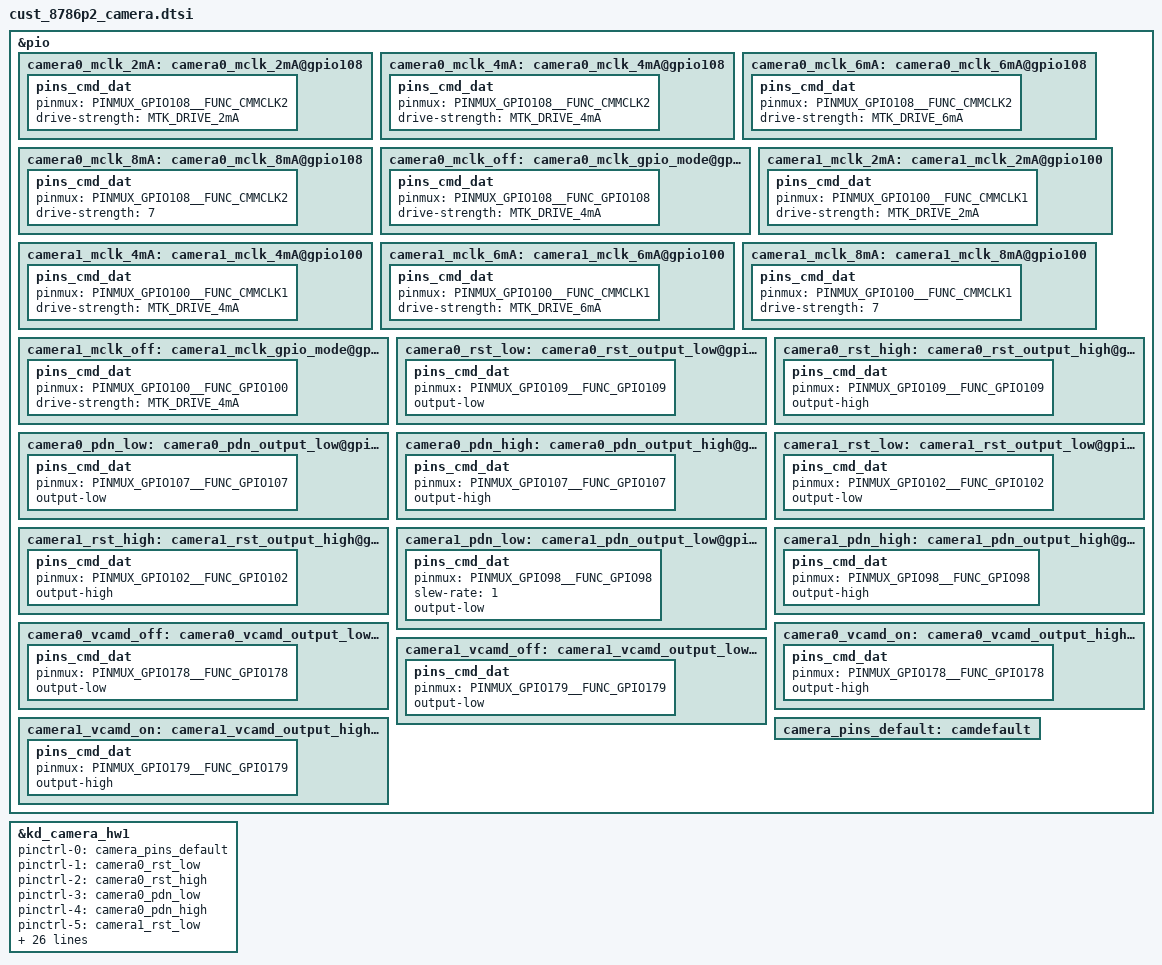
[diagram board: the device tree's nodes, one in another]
// SPDX-License-Identifier: GPL-2.0
/*
 * Copyright (c) 2018 MediaTek Inc.
 */
/* CAMERA GPIO standardization */
&pio {
	camera0_mclk_2mA: camera0_mclk_2mA@gpio108 {
		pins_cmd_dat {
			pinmux = <PINMUX_GPIO108__FUNC_CMMCLK2>;
			drive-strength = <MTK_DRIVE_2mA>;
		};
	};
	camera0_mclk_4mA: camera0_mclk_4mA@gpio108 {
		pins_cmd_dat {
			pinmux = <PINMUX_GPIO108__FUNC_CMMCLK2>;
			drive-strength = <MTK_DRIVE_4mA>;
		};
	};
	camera0_mclk_6mA: camera0_mclk_6mA@gpio108 {
		pins_cmd_dat {
			pinmux = <PINMUX_GPIO108__FUNC_CMMCLK2>;
			drive-strength = <MTK_DRIVE_6mA>;
		};
	};
	camera0_mclk_8mA: camera0_mclk_8mA@gpio108 {
		pins_cmd_dat {
			pinmux = <PINMUX_GPIO108__FUNC_CMMCLK2>;
			drive-strength = <7>;
		};
	};
	camera0_mclk_off: camera0_mclk_gpio_mode@gpio108 {
		pins_cmd_dat {
			pinmux = <PINMUX_GPIO108__FUNC_GPIO108>;
			drive-strength = <MTK_DRIVE_4mA>;
		};
	};
	camera1_mclk_2mA: camera1_mclk_2mA@gpio100 {
		pins_cmd_dat {
			pinmux = <PINMUX_GPIO100__FUNC_CMMCLK1>;
			drive-strength = <MTK_DRIVE_2mA>;
		};
	};
	camera1_mclk_4mA: camera1_mclk_4mA@gpio100 {
		pins_cmd_dat {
			pinmux = <PINMUX_GPIO100__FUNC_CMMCLK1>;
			drive-strength = <MTK_DRIVE_4mA>;
		};
	};
	camera1_mclk_6mA: camera1_mclk_6mA@gpio100 {
		pins_cmd_dat {
			pinmux = <PINMUX_GPIO100__FUNC_CMMCLK1>;
			drive-strength = <MTK_DRIVE_6mA>;
		};
	};
	camera1_mclk_8mA: camera1_mclk_8mA@gpio100 {
		pins_cmd_dat {
			pinmux = <PINMUX_GPIO100__FUNC_CMMCLK1>;
			drive-strength = <7>;
		};
	};
	camera1_mclk_off: camera1_mclk_gpio_mode@gpio100 {
		pins_cmd_dat {
			pinmux = <PINMUX_GPIO100__FUNC_GPIO100>;
			drive-strength = <MTK_DRIVE_4mA>;
		};
	};
	camera0_rst_low: camera0_rst_output_low@gpio109 {
		pins_cmd_dat {
			pinmux = <PINMUX_GPIO109__FUNC_GPIO109>;
			output-low;
		};
	};
	camera0_rst_high: camera0_rst_output_high@gpio109 {
		pins_cmd_dat {
			pinmux = <PINMUX_GPIO109__FUNC_GPIO109>;
			output-high;
		};
	};
	camera0_pdn_low: camera0_pdn_output_low@gpio107 {
		pins_cmd_dat {
			pinmux = <PINMUX_GPIO107__FUNC_GPIO107>;
			output-low;
		};
	};
	camera0_pdn_high: camera0_pdn_output_high@gpio107 {
		pins_cmd_dat {
			pinmux = <PINMUX_GPIO107__FUNC_GPIO107>;
			output-high;
		};
	};
	camera1_rst_low: camera1_rst_output_low@gpio102 {
		pins_cmd_dat {
			pinmux = <PINMUX_GPIO102__FUNC_GPIO102>;
			output-low;
		};
	};
	camera1_rst_high: camera1_rst_output_high@gpio102 {
		pins_cmd_dat {
			pinmux = <PINMUX_GPIO102__FUNC_GPIO102>;
			output-high;
		};
	};
	camera1_pdn_low: camera1_pdn_output_low@gpio98 {
		pins_cmd_dat {
			pinmux = <PINMUX_GPIO98__FUNC_GPIO98>;
			slew-rate = <1>;
			output-low;
		};
	};
	camera1_pdn_high: camera1_pdn_output_high@gpio98 {
		pins_cmd_dat {
			pinmux = <PINMUX_GPIO98__FUNC_GPIO98>;
			output-high;
		};
	};
	camera0_vcamd_off: camera0_vcamd_output_low@gpio178 {
		pins_cmd_dat {
			pinmux = <PINMUX_GPIO178__FUNC_GPIO178>;
			output-low;
		};
	};
	camera0_vcamd_on: camera0_vcamd_output_high@gpio178 {
		pins_cmd_dat {
			pinmux = <PINMUX_GPIO178__FUNC_GPIO178>;
			output-high;
		};
	};
	camera1_vcamd_off: camera1_vcamd_output_low@gpio179 {
		pins_cmd_dat {
			pinmux = <PINMUX_GPIO179__FUNC_GPIO179>;
			output-low;
		};
	};
	camera1_vcamd_on: camera1_vcamd_output_high@gpio179 {
		pins_cmd_dat {
			pinmux = <PINMUX_GPIO179__FUNC_GPIO179>;
			output-high;
		};
	};
	camera_pins_default: camdefault {
	};

};

&kd_camera_hw1 {
	pinctrl-names = "default",
			"cam0_rst0", "cam0_rst1",
			"cam0_pnd0", "cam0_pnd1",
			"cam1_rst0", "cam1_rst1",
			"cam1_pnd0", "cam1_pnd1",
			"cam0_vcamd_on",
			"cam0_vcamd_off",
			"cam1_vcamd_on",
			"cam1_vcamd_off",
			"cam0_mclk_off",
			"cam0_mclk_2mA", "cam0_mclk_4mA",
			"cam0_mclk_6mA", "cam0_mclk_8mA",
			"cam1_mclk_off",
			"cam1_mclk_2mA", "cam1_mclk_4mA",
			"cam1_mclk_6mA", "cam1_mclk_8mA";


	pinctrl-0 = <&camera_pins_default>;
	pinctrl-1 = <&camera0_rst_low>;
	pinctrl-2 = <&camera0_rst_high>;
	pinctrl-3 = <&camera0_pdn_low>;
	pinctrl-4 = <&camera0_pdn_high>;
	pinctrl-5 = <&camera1_rst_low>;
	pinctrl-6 = <&camera1_rst_high>;
	pinctrl-7 = <&camera1_pdn_low>;
	pinctrl-8 = <&camera1_pdn_high>;
	pinctrl-9 = <&camera0_vcamd_on>;
	pinctrl-10 = <&camera0_vcamd_off>;
	pinctrl-11 = <&camera1_vcamd_on>;
	pinctrl-12 = <&camera1_vcamd_off>;
	pinctrl-13 = <&camera0_mclk_off>;
	pinctrl-14 = <&camera0_mclk_2mA>;
	pinctrl-15 = <&camera0_mclk_4mA>;
	pinctrl-16 = <&camera0_mclk_6mA>;
	pinctrl-17 = <&camera0_mclk_8mA>;
	pinctrl-18 = <&camera1_mclk_off>;
	pinctrl-19 = <&camera1_mclk_2mA>;
	pinctrl-20 = <&camera1_mclk_4mA>;
	pinctrl-21 = <&camera1_mclk_6mA>;
	pinctrl-22 = <&camera1_mclk_8mA>;

	cam0_vcama-supply = <&mt_pmic_vcama1_ldo_reg>;
	cam1_vcama-supply = <&mt_pmic_vcama2_ldo_reg>;
	//cam0_vcamd-supply = <&mt_pmic_vcamd_ldo_reg>;
	cam1_vcamd-supply = <&mt_pmic_vcamd_ldo_reg>;
	cam0_vcamio-supply = <&mt_pmic_vcamio_ldo_reg>;
	cam1_vcamio-supply = <&mt_pmic_vcamio_ldo_reg>;
	cam0_enable_sensor = "gc08a3_mipi_raw ov13b10_mipi_raw ov13b10txd_mipi_raw s5k4h7_mipi_raw";
	cam1_enable_sensor = "gc08a3sub_mipi_raw s5k4h7sub_mipi_raw";
	status = "okay";

};
/* CAMERA GPIO end */
